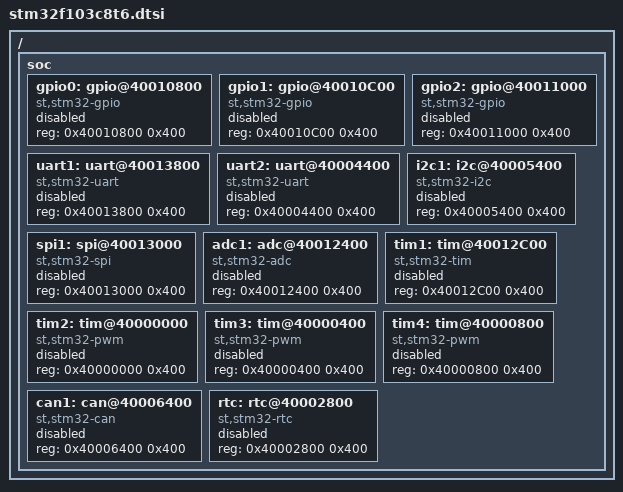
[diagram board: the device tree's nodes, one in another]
/*
 * stm32f103c8t6.dtsi — STM32F103C8T6 SoC 级外设描述
 *
 * 外设地址参考 STM32F103x8 (RM0008 Rev 21):
 *   - APB1:  0x40000000 – 0x40007FFF
 *   - APB2:  0x40010000 – 0x40013FFF
 */
#ifndef _SOC_STM32F103C8T6_DTSI
#define _SOC_STM32F103C8T6_DTSI

/ {
    soc {
        #address-cells = <1>;
        #size-cells = <1>;

        gpio0: gpio@40010800 {
            compatible = "st,stm32-gpio";
            reg = <0x40010800 0x400>;   /* GPIOA */
            status = "disabled";
        };

        gpio1: gpio@40010C00 {
            compatible = "st,stm32-gpio";
            reg = <0x40010C00 0x400>;   /* GPIOB */
            status = "disabled";
        };

        gpio2: gpio@40011000 {
            compatible = "st,stm32-gpio";
            reg = <0x40011000 0x400>;   /* GPIOC */
            status = "disabled";
        };

        uart1: uart@40013800 {
            compatible = "st,stm32-uart";
            reg = <0x40013800 0x400>;   /* USART1 */
            status = "disabled";
        };

        uart2: uart@40004400 {
            compatible = "st,stm32-uart";
            reg = <0x40004400 0x400>;   /* USART2 */
            status = "disabled";
        };

        i2c1: i2c@40005400 {
            compatible = "st,stm32-i2c";
            reg = <0x40005400 0x400>;   /* I2C1 */
            status = "disabled";
        };

        spi1: spi@40013000 {
            compatible = "st,stm32-spi";
            reg = <0x40013000 0x400>;   /* SPI1 */
            status = "disabled";
        };

        adc1: adc@40012400 {
            compatible = "st,stm32-adc";
            reg = <0x40012400 0x400>;   /* ADC1 */
            status = "disabled";
        };

        tim1: tim@40012C00 {
            compatible = "st,stm32-tim";
            reg = <0x40012C00 0x400>;   /* TIM1 */
            status = "disabled";
        };

        tim2: tim@40000000 {
            compatible = "st,stm32-pwm";
            reg = <0x40000000 0x400>;   /* TIM2 */
            status = "disabled";
        };

        tim3: tim@40000400 {
            compatible = "st,stm32-pwm";
            reg = <0x40000400 0x400>;   /* TIM3 */
            status = "disabled";
        };

        tim4: tim@40000800 {
            compatible = "st,stm32-pwm";
            reg = <0x40000800 0x400>;   /* TIM4 */
            status = "disabled";
        };

        can1: can@40006400 {
            compatible = "st,stm32-can";
            reg = <0x40006400 0x400>;   /* CAN1 / bxCAN */
            status = "disabled";
        };

        rtc: rtc@40002800 {
            compatible = "st,stm32-rtc";
            reg = <0x40002800 0x400>;   /* RTC */
            status = "disabled";
        };
    };
};

#endif /* _SOC_STM32F103C8T6_DTSI */
